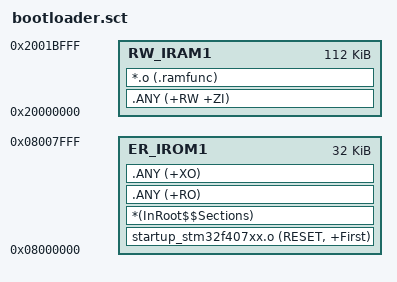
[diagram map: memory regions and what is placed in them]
; *************************************************************
; *** Bootloader Scatter-Loading Description File
; *** ROM: 0x08000000, 32KB (S0+S1)
; *** RAM: 0x20000000, 112KB (不使用 CCM)
; *************************************************************

LR_IROM1 0x08000000 0x00008000  {    ; load region size_region (32KB)
  ER_IROM1 0x08000000 0x00008000  {  ; load address = execution address
    startup_stm32f407xx.o (RESET, +First)
    *(InRoot$$Sections)
    .ANY (+RO)
    .ANY (+XO)
  }
  RW_IRAM1 0x20000000 0x0001C000  {  ; RW data (112KB)
    .ANY (+RW +ZI)
    *.o (.ramfunc)
  }
}
